# IMM100A register map
Vendor: Infineon; File version: 0.8.0 (Reference Manual v0.8.0)
CPU: CM0 r0p0, little endian, no MPU, no FPU, 2 interrupt priority bits
Registers are 32-bit, read-write, reset 0x0 unless marked. A register's access mark holds for its fields unless they carry their own. Offsets are from the block's base; [hi:lo] are bit positions; {n}, {i} and the like mark numbered series.

## SCU_INTERRUPT — System Control Unit
Base 0x40010038
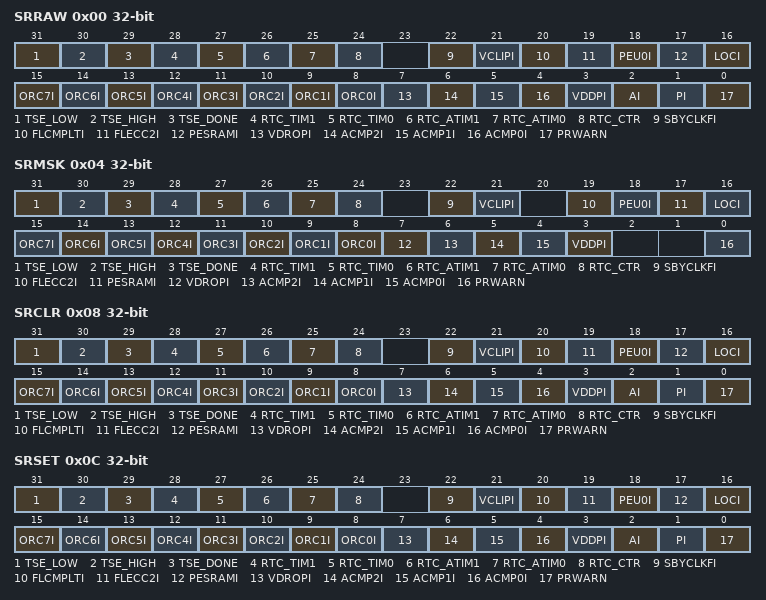
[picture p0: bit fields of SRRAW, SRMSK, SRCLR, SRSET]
0x00 SRRAW ro — SCU Raw Service Request Status
  [31] TSE_LOW — DTS Compare Low Temperature Event Status Before Masking
  [30] TSE_HIGH — DTS Compare High Temperature Event Status Before Masking
  [29] TSE_DONE — DTS Measurement Done Event Status Before Masking
  [28] RTC_TIM1 — RTC TIM1 Mirror Register Update Status Before Masking
  [27] RTC_TIM0 — RTC TIM0 Mirror Register Update Before Masking
  [26] RTC_ATIM1 — RTC ATIM1 Mirror Register Update Status Before Masking
  [25] RTC_ATIM0 — RTC ATIM0 Mirror Register Update Status Before Masking
  [24] RTC_CTR — RTC CTR Mirror Register Update Status Before Masking
  [22] SBYCLKFI — Standby Clock Failure Event Status Before Masking
  [21] VCLIPI — VCLIP Event Status Before Masking
  [20] FLCMPLTI — Flash Operation Complete Event Status Before Masking
  [19] FLECC2I — Flash Double Bit ECC Event Status Before Masking
  [18] PEU0I — USIC0 SRAM Parity Error Event Status Before Masking
  [17] PESRAMI — 16kbytes SRAM Parity Error Event Status Before Masking
  [16] LOCI — Loss of DCO1 Clock Event Status Before Masking
  [n+8] ORC{n}I (n=0..7) — Out of Range Comparator X Event Status Before Masking
  [7] VDROPI — VDROP Event Status Before Masking
  [6] ACMP2I — Analog Comparator 2 Event Status Before Masking
  [5] ACMP1I — Analog Comparator 1 Event Status Before Masking
  [4] ACMP0I — Analog Comparator 0 Event Status Before Masking
  [3] VDDPI — VDDP pre-warning Event Status Before Masking
  [2] AI — RTC Raw Alarm Event Status Before Masking
  [1] PI — RTC Raw Periodic Event Status Before Masking
  [0] PRWARN — WDT pre-warning Event Status Before Masking
0x04 SRMSK — SCU Service Request Mask
  [31] TSE_LOW — DTS Compare Low Temperature Interrupt Mask
  [30] TSE_HIGH — DTS Compare High Temperature Interrupt Mask
  [29] TSE_DONE — DTS Measurement Done Interrupt Mask
  [28] RTC_TIM1 — RTC TIM1 Mirror Register Update Mask
  [27] RTC_TIM0 — RTC TIM0 Mirror Register Update Mask
  [26] RTC_ATIM1 — RTC ATIM1 Mirror Register Update Mask
  [25] RTC_ATIM0 — RTC ATIM0 Mirror Register Update Mask
  [24] RTC_CTR — RTC CTR Mirror Register Update Mask
  [22] SBYCLKFI — Standby Clock Failure Interrupt Mask
  [21] VCLIPI — VCLIP Interrupt Mask
  [19] FLECC2I — Flash Double Bit ECC Interrupt Mask
  [18] PEU0I — USIC0 SRAM Parity Error Interrupt Mask
  [17] PESRAMI — 16kbytes SRAM Parity Error Interrupt Mask
  [16] LOCI — Loss of DCO1 Clock Interrupt Mask
  [n+8] ORC{n}I (n=0..7) — Out of Range Comparator X Interrupt Mask
  [7] VDROPI — VDROP Interrupt Mask
  [6] ACMP2I — Analog Comparator 2 Interrupt Mask
  [5] ACMP1I — Analog Comparator 1 Interrupt Mask
  [4] ACMP0I — Analog Comparator 0 Interrupt Mask
  [3] VDDPI — VDDP pre-warning Interrupt Mask
  [0] PRWARN — WDT pre-warning Interrupt Mask
0x08 SRCLR wo — SCU Service Request Clear
  [31] TSE_LOW — DTS Compare Low Temperature Interrupt Clear
  [30] TSE_HIGH — DTS Compare High Temperature Interrupt Clear
  [29] TSE_DONE — DTS Measurement Done Interrupt Clear
  [28] RTC_TIM1 — RTC TIM1 Mirror Register Update Clear
  [27] RTC_TIM0 — RTC TIM0 Mirror Register Update Clear
  [26] RTC_ATIM1 — RTC ATIM1 Mirror Register Update Clear
  [25] RTC_ATIM0 — RTC ATIM0 Mirror Register Update Clear
  [24] RTC_CTR — RTC CTR Mirror Register Update Clear
  [22] SBYCLKFI — Standby Clock Failure Interrupt Clear
  [21] VCLIPI — VCLIP Interrupt Clear
  [20] FLCMPLTI — Flash Operation Complete Interrupt Clear
  [19] FLECC2I — Flash Double Bit ECC Interrupt Clear
  [18] PEU0I — USIC0 SRAM Parity Error Interrupt Clear
  [17] PESRAMI — 16kbytes SRAM Parity Error Interrupt Clear
  [16] LOCI — Loss of DCO1 Clock Interrupt Clear
  [n+8] ORC{n}I (n=0..7) — Out of Range Comparator X Interrupt Clear
  [7] VDROPI — VDROP Interrupt Clear
  [6] ACMP2I — Analog Comparator 2 Interrupt Clear
  [5] ACMP1I — Analog Comparator 1 Interrupt Clear
  [4] ACMP0I — Analog Comparator 0 Interrupt Clear
  [3] VDDPI — VDDP pre-warning Interrupt Clear
  [2] AI — RTC Alarm Interrupt Clear
  [1] PI — RTC Periodic Interrupt Clear
  [0] PRWARN — WDT pre-warning Interrupt Clear
0x0C SRSET wo — SCU Service Request Set
  [31] TSE_LOW — DTS Compare Low Temperature Interrupt Set
  [30] TSE_HIGH — DTS Compare High Temperature Interrupt Set
  [29] TSE_DONE — DTS Measurement Done Interrupt Set
  [28] RTC_TIM1 — RTC TIM1 Mirror Register Update Set
  [27] RTC_TIM0 — RTC TIM0 Mirror Register Update Set
  [26] RTC_ATIM1 — RTC ATIM1 Mirror Register Update Set
  [25] RTC_ATIM0 — RTC ATIM0 Mirror Register Update Set
  [24] RTC_CTR — RTC CTR Mirror Register Update Set
  [22] SBYCLKFI — Standby Clock Failure Interrupt Set
  [21] VCLIPI — VCLIP Interrupt Set
  [20] FLCMPLTI — Flash Operation Complete Interrupt Set
  [19] FLECC2I — Flash Double Bit ECC Interrupt Set
  [18] PEU0I — USIC0 SRAM Parity Error Interrupt Set
  [17] PESRAMI — 16kbytes SRAM Parity Error Interrupt Set
  [16] LOCI — Loss of DCO1 Clock Interrupt Set
  [n+8] ORC{n}I (n=0..7) — Out of Range Comparator X Interrupt Set
  [7] VDROPI — VDROP Interrupt Set
  [6] ACMP2I — Analog Comparator 2 Interrupt Set
  [5] ACMP1I — Analog Comparator 1 Interrupt Set
  [4] ACMP0I — Analog Comparator 0 Interrupt Set
  [3] VDDPI — VDDP pre-warning Interrupt Set
  [2] AI — RTC Alarm Interrupt Set
  [1] PI — RTC Periodic Interrupt Set
  [0] PRWARN — WDT pre-warning Interrupt Set
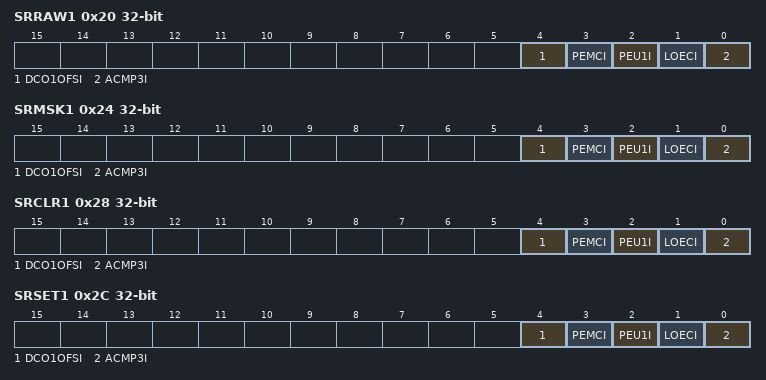
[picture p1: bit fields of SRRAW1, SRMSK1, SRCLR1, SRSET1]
0x20 SRRAW1 ro — SCU Raw Service Request Status 1
  [4] DCO1OFSI — DCO1 Out of SYNC Event Status Before Masking
  [3] PEMCI — MultiCAN SRAM Parity Error Event Status Before Masking
  [2] PEU1I — USIC1 SRAM Parity Error Event Status Before Masking
  [1] LOECI — Loss of External OSC_HP Clock Event Status Before Masking
  [0] ACMP3I — Analog Comparator 3 Event Status Before Masking
0x24 SRMSK1 — SCU Service Request Mask 1
  [4] DCO1OFSI — DCO1 Out of SYNC Interrupt Mask
  [3] PEMCI — MultiCAN SRAM Parity Error Interrupt Mask
  [2] PEU1I — USIC1 SRAM Parity Error Interrupt Mask
  [1] LOECI — Loss of External OSC_HP Clock Interrupt Mask
  [0] ACMP3I — Analog Comparator 3 Interrupt Mask
0x28 SRCLR1 wo — SCU Service Request Clear 1
  [4] DCO1OFSI — DCO1 Out of SYNC Interrupt Clear
  [3] PEMCI — MultiCAN SRAM Parity Error Interrupt Clear
  [2] PEU1I — USIC1 SRAM Parity Error Interrupt Clear
  [1] LOECI — Loss of External OSC_HP Clock Interrupt Clear
  [0] ACMP3I — Analog Comparator 3 Interrupt Clear
0x2C SRSET1 wo — SCU Service Request Set 1
  [4] DCO1OFSI — DCO1 Out of SYNC Interrupt Set
  [3] PEMCI — MultiCAN SRAM Parity Error Interrupt Set
  [2] PEU1I — USIC1 SRAM Parity Error Interrupt Set
  [1] LOECI — Loss of External OSC_HP Clock Interrupt Set
  [0] ACMP3I — Analog Comparator 3 Interrupt Set
